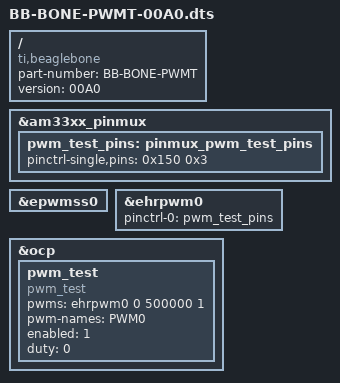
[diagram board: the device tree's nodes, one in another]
/*
 * Copyright (C) 2013 CircuitCo
 *
 * This program is free software; you can redistribute it and/or modify
 * it under the terms of the GNU General Public License version 2 as
 * published by the Free Software Foundation.
 */
/dts-v1/;
/plugin/;

/ {
	compatible = "ti,beaglebone", "ti,beaglebone-black";

	/* identification */
	part-number = "BB-BONE-PWMT";
	version = "00A0";

	fragment@0 {
		target = <&am33xx_pinmux>;
		__overlay__ {
			pwm_test_pins: pinmux_pwm_test_pins {
				pinctrl-single,pins = <0x150  0x3>; /* spi0_sclk = ehrpwm0A = P9_14 = Heater_HBP  | MODE 3 */
			};
		};
	};

	fragment@1 {
		target = <&epwmss0>;
		__overlay__ {
			status = "okay";
		};
	};

	fragment@2 {
		target = <&ehrpwm0>;
		__overlay__ {
			pinctrl-names	= "default";
			pinctrl-0	= <&pwm_test_pins>;
			status = "okay";
		};
	};

	fragment@3 {
		target = <&ocp>;
		__overlay__ {
			pwm_test {
				compatible	= "pwm_test";
				pwms 		= <&ehrpwm0 0 500000 1>;
				pwm-names 	= "PWM0";
				enabled		= <1>;
				duty		= <0>;
				status 		= "okay";
			};
		};
	};
};
